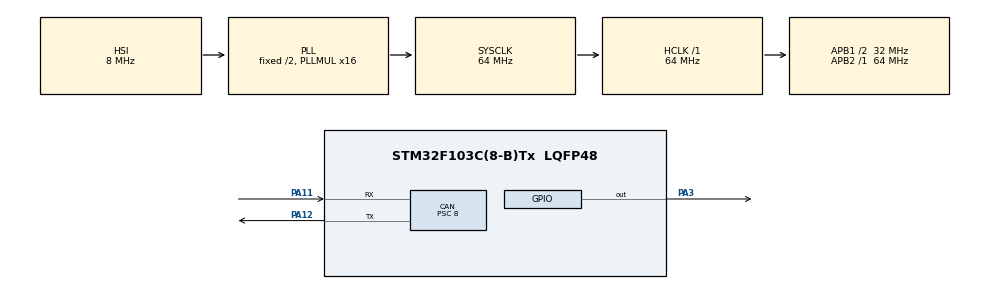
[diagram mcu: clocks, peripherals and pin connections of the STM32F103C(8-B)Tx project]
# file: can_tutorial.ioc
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CAN.BS1=CAN_BS1_3TQ
CAN.BS2=CAN_BS2_4TQ
CAN.CalculateBaudRate=500000
CAN.CalculateTimeBit=2000.00
CAN.CalculateTimeQuantum=250.0
CAN.Prescaler=8
Mcu.Family=STM32F1
Mcu.Name=STM32F103C(8-B)Tx
Mcu.Package=LQFP48
NVIC.PriorityGroup=NVIC_PRIORITYGROUP_4
NVIC.USB_LP_CAN1_RX0_IRQn=true\:0\:0\:false\:false\:true\:true\:true
PA11.Mode=CAN_Activate
PA11.Signal=CAN_RX
PA12.Mode=CAN_Activate
PA12.Signal=CAN_TX
PA13.Mode=Trace_Asynchronous_SW
PA13.Signal=SYS_JTMS-SWDIO
PA14.Mode=Trace_Asynchronous_SW
PA14.Signal=SYS_JTCK-SWCLK
PA3.Signal=GPIO_Output
PB3.Mode=Trace_Asynchronous_SW
PB3.Signal=SYS_JTDO-TRACESWO
PD0-OSC_IN.Signal=RCC_OSC_IN
PD1-OSC_OUT.Signal=RCC_OSC_OUT
ProjectManager.HeapSize=0x200
ProjectManager.StackSize=0x400
ProjectManager.TargetToolchain=STM32CubeIDE
RCC.AHBFreq_Value=64000000
RCC.APB1CLKDivider=RCC_HCLK_DIV2
RCC.APB1Freq_Value=32000000
RCC.APB1TimFreq_Value=64000000
RCC.APB2Freq_Value=64000000
RCC.APB2TimFreq_Value=64000000
RCC.HCLKFreq_Value=64000000
RCC.PLLMUL=RCC_PLL_MUL16
RCC.SYSCLKFreq_VALUE=64000000
RCC.SYSCLKSource=RCC_SYSCLKSOURCE_PLLCLK
RCC.USBFreq_Value=64000000
board=custom

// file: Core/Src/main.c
/* USER CODE BEGIN Header */
/**
  ******************************************************************************
  * @file           : main.c
  * @brief          : Main program body
  ******************************************************************************
  * @attention
  *
  * <h2><center>&copy; Copyright (c) 2021 STMicroelectronics.
  * All rights reserved.</center></h2>
  *
  * This software component is licensed by ST under BSD 3-Clause license,
  * the "License"; You may not use this file except in compliance with the
  * License. You may obtain a copy of the License at:
  *                        opensource.org/licenses/BSD-3-Clause
  *
  ******************************************************************************
  */
/* USER CODE END Header */
#include "main.h"

CAN_HandleTypeDef hcan;

void SystemClock_Config(void);
static void MX_GPIO_Init(void);
static void MX_CAN_Init(void);

/* USER CODE BEGIN 0 */

int _write(int32_t file, uint8_t *ptr, int32_t len){
    int i = 0;
    for (i=0; i<len; i++){
        ITM_SendChar((*ptr++));
    }
    return len;
}

/* USER CODE END 0 */

int main(void)
{

  /* MCU Configuration--------------------------------------------------------*/

  /* Reset of all peripherals, Initializes the Flash interface and the Systick. */
  HAL_Init();

  /* Configure the system clock */
  SystemClock_Config();

  /* Initialize all configured peripherals */
  MX_GPIO_Init();
  MX_CAN_Init();

  /* Infinite loop */
  /* USER CODE BEGIN WHILE */
  while (1)
  {

	  uint32_t mb;
	  CAN_TxHeaderTypeDef msg;
	  uint8_t data[] = "Hello!";

	  msg.StdId = 127;
	  msg.IDE = CAN_ID_STD;
	  msg.RTR = CAN_RTR_DATA;
	  msg.DLC = 6;
	  msg.TransmitGlobalTime = DISABLE;

	  if (HAL_CAN_AddTxMessage(&hcan, &msg, data, &mb) != HAL_OK) {
	    Error_Handler();
	  }

	  printf("send message: %s\n", data);

    /* USER CODE END WHILE */

  }
}

void SystemClock_Config(void)
{
  RCC_OscInitTypeDef RCC_OscInitStruct = {0};
  RCC_ClkInitTypeDef RCC_ClkInitStruct = {0};

  /** Initializes the RCC Oscillators according to the specified parameters
  * in the RCC_OscInitTypeDef structure.
  */
  RCC_OscInitStruct.OscillatorType = RCC_OSCILLATORTYPE_HSI;
  RCC_OscInitStruct.HSIState = RCC_HSI_ON;
  RCC_OscInitStruct.HSICalibrationValue = RCC_HSICALIBRATION_DEFAULT;
  RCC_OscInitStruct.PLL.PLLState = RCC_PLL_ON;
  RCC_OscInitStruct.PLL.PLLSource = RCC_PLLSOURCE_HSI_DIV2;
  RCC_OscInitStruct.PLL.PLLMUL = RCC_PLL_MUL16;
  if (HAL_RCC_OscConfig(&RCC_OscInitStruct) != HAL_OK)
  {
    Error_Handler();
  }
  /** Initializes the CPU, AHB and APB buses clocks
  */
  RCC_ClkInitStruct.ClockType = RCC_CLOCKTYPE_HCLK|RCC_CLOCKTYPE_SYSCLK
                              |RCC_CLOCKTYPE_PCLK1|RCC_CLOCKTYPE_PCLK2;
  RCC_ClkInitStruct.SYSCLKSource = RCC_SYSCLKSOURCE_PLLCLK;
  RCC_ClkInitStruct.AHBCLKDivider = RCC_SYSCLK_DIV1;
  RCC_ClkInitStruct.APB1CLKDivider = RCC_HCLK_DIV2;
  RCC_ClkInitStruct.APB2CLKDivider = RCC_HCLK_DIV1;

  if (HAL_RCC_ClockConfig(&RCC_ClkInitStruct, FLASH_LATENCY_2) != HAL_OK)
  {
    Error_Handler();
  }
}

static void MX_CAN_Init(void)
{

}

static void MX_GPIO_Init(void)
{
  GPIO_InitTypeDef GPIO_InitStruct = {0};

  /* GPIO Ports Clock Enable */
  __HAL_RCC_GPIOD_CLK_ENABLE();
  __HAL_RCC_GPIOA_CLK_ENABLE();
  __HAL_RCC_GPIOB_CLK_ENABLE();

  /*Configure GPIO pin Output Level */
  HAL_GPIO_WritePin(GPIOA, GPIO_PIN_3, GPIO_PIN_RESET);

  /*Configure GPIO pin : PA3 */
  GPIO_InitStruct.Pin = GPIO_PIN_3;
  GPIO_InitStruct.Mode = GPIO_MODE_OUTPUT_PP;
  GPIO_InitStruct.Pull = GPIO_NOPULL;
  GPIO_InitStruct.Speed = GPIO_SPEED_FREQ_LOW;
  HAL_GPIO_Init(GPIOA, &GPIO_InitStruct);

}

/* USER CODE BEGIN 4 */

void can_irq(CAN_HandleTypeDef *pcan) {
  CAN_RxHeaderTypeDef msg;
  uint8_t data[8];
  HAL_CAN_GetRxMessage(pcan, CAN_RX_FIFO0, &msg, data);
  // do something
}

/* USER CODE END 4 */

void Error_Handler(void)
{
  __disable_irq();
  while (1)
  {
  }
}

/************************ (C) COPYRIGHT STMicroelectronics *****END OF FILE****/
